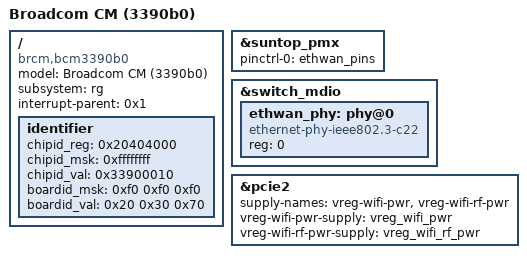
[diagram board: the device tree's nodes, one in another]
/dts-v1/;

/ {
	model = "Broadcom CM (3390b0)";
	compatible = "brcm,bcm3390b0", "brcm,brcmstb";
	subsystem = "rg";
	#address-cells = <0x2>;
	#size-cells = <0x2>;
	interrupt-parent = <0x1>;

	identifier {
		/* register offset */
		chipid_reg = < 0x20404000 >;
		chipid_msk = < 0xffffffff >;
		chipid_val = < 0x33900010 >;
		boardid_msk = < 0xf0 0xf0 0xf0 >;
		boardid_val = < 0x20 0x30 0x70 >;
	};
};

/include/ "rg.3390b0-bolt.dtsi"
/include/ "rg.3390-base.dtsi"
/include/ "rg.3390b0-moca.dtsi"
/include/ "rg.3390-wifi.dtsi"
/include/ "rg.3390-ethwan.dtsi"

/********************************************************************
 * any nodes that appear below are platform specific additions and
 * replacements.
 * The dtc will add or replace any properties in the nodes
 * below to the same nodes that appear in include files above.
 * If the property does not exist in the node above it will be added.
 * If the property does exist it will replace it.
 ********************************************************************/
&suntop_pmx {
	pinctrl-0 = <&ethwan_pins>;
};

&switch_mdio {
	ethwan_phy: phy@0 {	/* external bcm54210 */
		compatible = "ethernet-phy-ieee802.3-c22";
		reg = <0>;
	};
};

&pcie2 {
	supply-names = "vreg-wifi-pwr", "vreg-wifi-rf-pwr";
	vreg-wifi-pwr-supply = <&vreg_wifi_pwr>;
	vreg-wifi-rf-pwr-supply = <&vreg_wifi_rf_pwr>;
};
